# colorlight register map
Vendor: litex
Litex SoC 2026-11-18 18:20:01
Registers are 32-bit, read-write, reset 0x0 unless marked. A register's access mark holds for its fields unless they carry their own. Offsets are from the block's base; lines under a group give offsets from that group; [hi:lo] are bit positions; {n}, {i} and the like mark numbered series; 'fields as' and 'values as' point back to an identical list; <NAME> marks a mode.

## Memory map
0x80000000 ETHMEM size 0x4000
0xF0000000 SPIFLASH_MMAP size 0x14
0xF0000800 SPIFLASH_PHY size 0x4
0xF0001000 DMATEST size 0x18
0xF0001800 ETHPHY1 size 0x8
0xF0002000 CHAIN size 0x14
0xF0002800 PIXDMA size 0x68
0xF0003000 XBARPERF size 0x18
0xF0003800 CTRL size 0xC
0xF0004000 ETHMAC size 0xB4
0xF0004800 ETHPHY size 0x10
0xF0005000 HUB75_PALETTE size 0x4
0xF0005800 HUB75 size 0x90
0xF0006000 IDENTIFIER_MEM size 0x4
0xF0006800 SDRAM size 0x1C
0xF0007000 TIMER0 size 0x20
0xF0007800 UART size 0x20

## Interrupts
0 uart (UART)
1 timer0 (TIMER0)
2 ethmac (ETHMAC)

## Further device data
memoryRegions:
  ROM baseAddress=0x00000000 size=0x00010000
  SRAM baseAddress=0x10000000 size=0x00001000
  SPIFLASH baseAddress=0x80400000 size=0x00400000
  MAIN_RAM baseAddress=0x40000000 size=0x00400000
  MAIN_RAM_UNCACHED baseAddress=0x90000000 size=0x00400000
  ETHMAC baseAddress=0x80000000 size=0x00002000
  ETHMAC_RX baseAddress=0x80000000 size=0x00001000
  ETHMAC_TX baseAddress=0x80001000 size=0x00001000
  CSR baseAddress=0xF0000000 size=0x00010000
constants:
  CONFIG_PLATFORM_NAME value=colorlight_e320
  CONFIG_CLOCK_FREQUENCY value=35000000
  CONFIG_CPU_HAS_INTERRUPT value=None
  CONFIG_CPU_RESET_ADDR value=0
  CONFIG_CPU_HAS_ICACHE value=None
  CONFIG_CPU_TYPE_VEXRISCV value=None
  CONFIG_CPU_VARIANT_LITE value=None
  CONFIG_CPU_FAMILY value=riscv
  CONFIG_CPU_NAME value=vexriscv
  CONFIG_CPU_HUMAN_NAME value=VexRiscv_Lite
  CONFIG_CPU_NOP value=nop
  CONFIG_IDENTIFIER value=e320-128x256-icnd1065l-hub320-out4-v3.6.3 35MHz 2026-11-18 18:19:58
  FLASH_BOOT_ADDRESS value=2152726528
  SPIFLASH_PAGE_SIZE value=256
  CONFIG_L2_SIZE value=8192
  CHAIN_COUNTERS value=0
  RT_GEOM value=1
  RT_GEOM_MAX_COLUMNS value=128
  RT_GEOM_MAX_SCAN value=64
  ETH_PHY_NO_RESET value=None
  LOCALIP1 value=10
  LOCALIP2 value=11
  LOCALIP3 value=6
  LOCALIP4 value=250
  REMOTEIP1 value=10
  REMOTEIP2 value=11
  REMOTEIP3 value=6
  REMOTEIP4 value=65
  ETH_UDP_BROADCAST value=None
  TFTP_SERVER_PORT value=6969
  SDRAM_TEST_DISABLE value=None
  CONFIG_CSR_DATA_WIDTH value=32
  CONFIG_CSR_ALIGNMENT value=32
  CONFIG_CSR_ORDERING_BIG value=None
  CONFIG_BUS_STANDARD value=wishbone
  CONFIG_BUS_DATA_WIDTH value=32
  CONFIG_BUS_ADDRESS_WIDTH value=32
  CONFIG_BUS_BURSTING value=0
  CHAIN_DISC_PORT value=6990
  DMATEST_DATA_WIDTH value=32
  ETHMAC_RX_SLOTS value=2
  ETHMAC_TX_SLOTS value=2
  ETHMAC_SLOT_SIZE value=2048
  CONFIG_CPU_INTERRUPTS value=3
  ETHMAC_INTERRUPT value=2
  TIMER0_INTERRUPT value=1
  UART_INTERRUPT value=0

## SPIFLASH_MMAP
Base 0xF0000000
0x00 MMAP_DUMMY_BITS
  [7:0] mmap_dummy_bits
0x04 MASTER_CS
  [0] master_cs
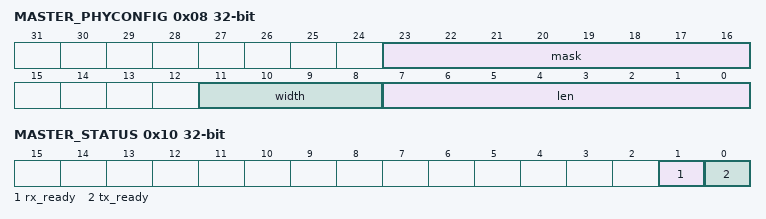
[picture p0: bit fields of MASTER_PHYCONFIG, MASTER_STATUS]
0x08 MASTER_PHYCONFIG — SPI PHY settings.
  [23:16] mask — SPI DQ output enable mask (set bits to ``1`` to enable output drivers on DQ lines).
  [11:8] width — SPI Xfer width (1/2/4/8).
  [7:0] len — SPI Xfer length (in bits).
0x0C MASTER_RXTX
0x10 MASTER_STATUS
  [1] rx_ready — RX FIFO is not empty.
  [0] tx_ready — TX FIFO is not full.

## SPIFLASH_PHY
Base 0xF0000800
0x00 CLK_DIVISOR reset 0x1
  [7:0] clk_divisor

## DMATEST
Base 0xF0001000
0x00 BASE — unused (tester not built)
  [23:0] base
0x04 LENGTH — unused (tester not built)
  [23:0] length
0x08 CTRL
  [0] start — unused (tester not built)
0x0C STATUS
  [0] busy — always 0 (tester not built)
0x10 CYCLES — always 0 (tester not built)
0x14 WRITTEN — always 0 (tester not built)

## ETHPHY1
Base 0xF0001800
0x00 CRG_RESET
  [0] crg_reset
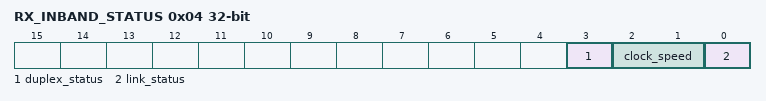
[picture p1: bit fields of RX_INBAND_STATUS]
0x04 RX_INBAND_STATUS
  [3] duplex_status, [2:1] clock_speed, [0] link_status
